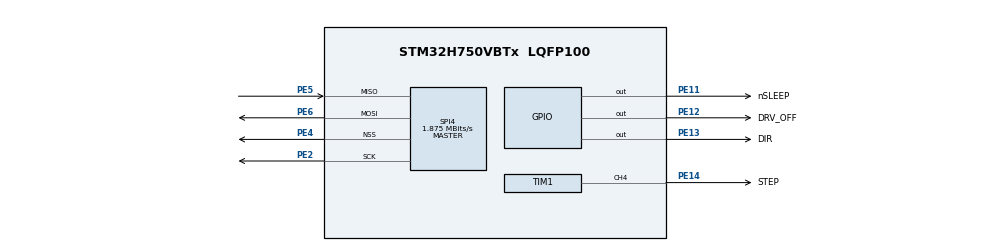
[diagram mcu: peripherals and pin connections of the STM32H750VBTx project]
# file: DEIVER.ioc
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CORTEX_M7.CPU_DCache=Enabled
CORTEX_M7.CPU_ICache=Enabled
Mcu.Family=STM32H7
Mcu.Name=STM32H750VBTx
Mcu.Package=LQFP100
NVIC.PriorityGroup=NVIC_PRIORITYGROUP_4
PE11.GPIO_Label=nSLEEP
PE11.GPIO_Speed=GPIO_SPEED_FREQ_MEDIUM
PE11.PinState=GPIO_PIN_SET
PE11.Signal=GPIO_Output
PE12.GPIO_Label=DRV_OFF
PE12.GPIO_Speed=GPIO_SPEED_FREQ_MEDIUM
PE12.Signal=GPIO_Output
PE13.GPIO_Label=DIR
PE13.GPIO_Speed=GPIO_SPEED_FREQ_MEDIUM
PE13.Signal=GPIO_Output
PE14.GPIO_Label=STEP
PE14.Signal=S_TIM1_CH4
PE2.Mode=Full_Duplex_Master
PE2.Signal=SPI4_SCK
PE4.Mode=NSS_Signal_Hard_Output
PE4.Signal=SPI4_NSS
PE5.Mode=Full_Duplex_Master
PE5.Signal=SPI4_MISO
PE6.Mode=Full_Duplex_Master
PE6.Signal=SPI4_MOSI
PH0-OSC_IN\ (PH0).Mode=HSE-External-Oscillator
PH0-OSC_IN\ (PH0).Signal=RCC_OSC_IN
PH1-OSC_OUT\ (PH1).Mode=HSE-External-Oscillator
PH1-OSC_OUT\ (PH1).Signal=RCC_OSC_OUT
ProjectManager.HeapSize=0x200
ProjectManager.StackSize=0x400
ProjectManager.TargetToolchain=MDK-ARM V5.27
RCC.ADCFreq_Value=50390625
RCC.APB1Freq_Value=120000000
RCC.APB2Freq_Value=120000000
RCC.APB3Freq_Value=120000000
RCC.APB4Freq_Value=120000000
RCC.CortexFreq_Value=480000000
RCC.D1PPRE=RCC_APB3_DIV2
RCC.D2PPRE1=RCC_APB1_DIV2
RCC.D2PPRE2=RCC_APB2_DIV2
RCC.D3PPRE=RCC_APB4_DIV2
RCC.DIVM1=5
RCC.DIVN1=192
RCC.HCLKFreq_Value=240000000
RCC.HPRE=RCC_HCLK_DIV2
RCC.PLLSourceVirtual=RCC_PLLSOURCE_HSE
RCC.SYSCLKFreq_VALUE=480000000
RCC.SYSCLKSource=RCC_SYSCLKSOURCE_PLLCLK
RCC.USBFreq_Value=480000000
SH.S_TIM1_CH4.0=TIM1_CH4,PWM Generation4 CH4
SPI4.BaudRatePrescaler=SPI_BAUDRATEPRESCALER_64
SPI4.CRCCalculation=SPI_CRCCALCULATION_DISABLE
SPI4.CalculateBaudRate=1.875 MBits/s
SPI4.DataSize=SPI_DATASIZE_16BIT
SPI4.Direction=SPI_DIRECTION_2LINES
SPI4.FifoThreshold=SPI_FIFO_THRESHOLD_08DATA
SPI4.Mode=SPI_MODE_MASTER
SPI4.NSSPolarity=SPI_NSS_POLARITY_LOW
SPI4.TIMode=SPI_TIMODE_ENABLE
SPI4.VirtualNSS=VM_NSSHARD
SPI4.VirtualType=VM_MASTER
TIM1.AutoReloadPreload=TIM_AUTORELOAD_PRELOAD_DISABLE
TIM1.Channel-PWM\ Generation4\ CH4=TIM_CHANNEL_4
TIM1.OCIdleState_4=TIM_OCIDLESTATE_SET
TIM1.Period=350
TIM1.Prescaler=239
TIM1.Pulse-PWM\ Generation4\ CH4=166
TIM1.RepetitionCounter=334
VP_TIM1_VS_ClockSourceINT.Mode=Internal
board=custom

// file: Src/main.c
/* USER CODE BEGIN Header */
/**
  ******************************************************************************
  * @file           : main.c
  * @brief          : Main program body
  ******************************************************************************
  * @attention
  *
  * <h2><center>&copy; Copyright (c) 2019 STMicroelectronics.
  * All rights reserved.</center></h2>
  *
  * This software component is licensed by ST under BSD 3-Clause license,
  * the "License"; You may not use this file except in compliance with the
  * License. You may obtain a copy of the License at:
  *                        opensource.org/licenses/BSD-3-Clause
  *
  ******************************************************************************
  */
/* USER CODE END Header */

#include "main.h"

/* USER CODE BEGIN Includes */
#include "drv8889.h"
/* USER CODE END Includes */

SPI_HandleTypeDef hspi4;

TIM_HandleTypeDef htim1;

void SystemClock_Config(void);
static void MX_GPIO_Init(void);
static void MX_SPI4_Init(void);
static void MX_TIM1_Init(void);

int main(void)
{

  /* Enable I-Cache---------------------------------------------------------*/
  SCB_EnableICache();

  /* Enable D-Cache---------------------------------------------------------*/
  SCB_EnableDCache();

  /* MCU Configuration--------------------------------------------------------*/

  /* Reset of all peripherals, Initializes the Flash interface and the Systick. */
  HAL_Init();

  /* Configure the system clock */
  SystemClock_Config();

  /* Initialize all configured peripherals */
  MX_GPIO_Init();
  MX_SPI4_Init();
  MX_TIM1_Init();
  /* USER CODE BEGIN 2 */
	HAL_TIM_PWM_Start(&htim1,TIM_CHANNEL_4);
	reset_Device8889();
  /* USER CODE END 2 */

  /* Infinite loop */
  while (1)
  {

  }
}

void SystemClock_Config(void)
{
  RCC_OscInitTypeDef RCC_OscInitStruct = {0};
  RCC_ClkInitTypeDef RCC_ClkInitStruct = {0};
  RCC_PeriphCLKInitTypeDef PeriphClkInitStruct = {0};

  /** Supply configuration update enable
  */
  HAL_PWREx_ConfigSupply(PWR_LDO_SUPPLY);
  /** Configure the main internal regulator output voltage
  */
  __HAL_PWR_VOLTAGESCALING_CONFIG(PWR_REGULATOR_VOLTAGE_SCALE0);

  while(!__HAL_PWR_GET_FLAG(PWR_FLAG_VOSRDY)) {}
  /** Initializes the CPU, AHB and APB busses clocks
  */
  RCC_OscInitStruct.OscillatorType = RCC_OSCILLATORTYPE_HSE;
  RCC_OscInitStruct.HSEState = RCC_HSE_ON;
  RCC_OscInitStruct.PLL.PLLState = RCC_PLL_ON;
  RCC_OscInitStruct.PLL.PLLSource = RCC_PLLSOURCE_HSE;
  RCC_OscInitStruct.PLL.PLLM = 5;
  RCC_OscInitStruct.PLL.PLLN = 192;
  RCC_OscInitStruct.PLL.PLLP = 2;
  RCC_OscInitStruct.PLL.PLLQ = 2;
  RCC_OscInitStruct.PLL.PLLR = 2;
  RCC_OscInitStruct.PLL.PLLRGE = RCC_PLL1VCIRANGE_2;
  RCC_OscInitStruct.PLL.PLLVCOSEL = RCC_PLL1VCOWIDE;
  RCC_OscInitStruct.PLL.PLLFRACN = 0;
  if (HAL_RCC_OscConfig(&RCC_OscInitStruct) != HAL_OK)
  {
    Error_Handler();
  }
  /** Initializes the CPU, AHB and APB busses clocks
  */
  RCC_ClkInitStruct.ClockType = RCC_CLOCKTYPE_HCLK|RCC_CLOCKTYPE_SYSCLK
                              |RCC_CLOCKTYPE_PCLK1|RCC_CLOCKTYPE_PCLK2
                              |RCC_CLOCKTYPE_D3PCLK1|RCC_CLOCKTYPE_D1PCLK1;
  RCC_ClkInitStruct.SYSCLKSource = RCC_SYSCLKSOURCE_PLLCLK;
  RCC_ClkInitStruct.SYSCLKDivider = RCC_SYSCLK_DIV1;
  RCC_ClkInitStruct.AHBCLKDivider = RCC_HCLK_DIV2;
  RCC_ClkInitStruct.APB3CLKDivider = RCC_APB3_DIV2;
  RCC_ClkInitStruct.APB1CLKDivider = RCC_APB1_DIV2;
  RCC_ClkInitStruct.APB2CLKDivider = RCC_APB2_DIV2;
  RCC_ClkInitStruct.APB4CLKDivider = RCC_APB4_DIV2;

  if (HAL_RCC_ClockConfig(&RCC_ClkInitStruct, FLASH_LATENCY_4) != HAL_OK)
  {
    Error_Handler();
  }
  PeriphClkInitStruct.PeriphClockSelection = RCC_PERIPHCLK_SPI4;
  PeriphClkInitStruct.Spi45ClockSelection = RCC_SPI45CLKSOURCE_D2PCLK1;
  if (HAL_RCCEx_PeriphCLKConfig(&PeriphClkInitStruct) != HAL_OK)
  {
    Error_Handler();
  }
}

static void MX_SPI4_Init(void)
{

  /* SPI4 parameter configuration*/
  hspi4.Instance = SPI4;
  hspi4.Init.Mode = SPI_MODE_MASTER;
  hspi4.Init.Direction = SPI_DIRECTION_2LINES;
  hspi4.Init.DataSize = SPI_DATASIZE_16BIT;
  hspi4.Init.NSS = SPI_NSS_HARD_OUTPUT;
  hspi4.Init.BaudRatePrescaler = SPI_BAUDRATEPRESCALER_64;
  hspi4.Init.TIMode = SPI_TIMODE_ENABLE;
  hspi4.Init.CRCCalculation = SPI_CRCCALCULATION_DISABLE;
  hspi4.Init.CRCPolynomial = 0x0;
  hspi4.Init.NSSPMode = SPI_NSS_PULSE_DISABLE;
  hspi4.Init.NSSPolarity = SPI_NSS_POLARITY_LOW;
  hspi4.Init.FifoThreshold = SPI_FIFO_THRESHOLD_08DATA;
  hspi4.Init.TxCRCInitializationPattern = SPI_CRC_INITIALIZATION_ALL_ZERO_PATTERN;
  hspi4.Init.RxCRCInitializationPattern = SPI_CRC_INITIALIZATION_ALL_ZERO_PATTERN;
  hspi4.Init.MasterReceiverAutoSusp = SPI_MASTER_RX_AUTOSUSP_DISABLE;
  hspi4.Init.MasterKeepIOState = SPI_MASTER_KEEP_IO_STATE_DISABLE;
  hspi4.Init.IOSwap = SPI_IO_SWAP_DISABLE;
  if (HAL_SPI_Init(&hspi4) != HAL_OK)
  {
    Error_Handler();
  }

}

static void MX_TIM1_Init(void)
{

  TIM_ClockConfigTypeDef sClockSourceConfig = {0};
  TIM_MasterConfigTypeDef sMasterConfig = {0};
  TIM_OC_InitTypeDef sConfigOC = {0};
  TIM_BreakDeadTimeConfigTypeDef sBreakDeadTimeConfig = {0};

  htim1.Instance = TIM1;
  htim1.Init.Prescaler = 239;
  htim1.Init.CounterMode = TIM_COUNTERMODE_UP;
  htim1.Init.Period = 350;
  htim1.Init.ClockDivision = TIM_CLOCKDIVISION_DIV1;
  htim1.Init.RepetitionCounter = 334;
  htim1.Init.AutoReloadPreload = TIM_AUTORELOAD_PRELOAD_DISABLE;
  if (HAL_TIM_Base_Init(&htim1) != HAL_OK)
  {
    Error_Handler();
  }
  sClockSourceConfig.ClockSource = TIM_CLOCKSOURCE_INTERNAL;
  if (HAL_TIM_ConfigClockSource(&htim1, &sClockSourceConfig) != HAL_OK)
  {
    Error_Handler();
  }
  if (HAL_TIM_PWM_Init(&htim1) != HAL_OK)
  {
    Error_Handler();
  }
  sMasterConfig.MasterOutputTrigger = TIM_TRGO_RESET;
  sMasterConfig.MasterOutputTrigger2 = TIM_TRGO2_RESET;
  sMasterConfig.MasterSlaveMode = TIM_MASTERSLAVEMODE_DISABLE;
  if (HAL_TIMEx_MasterConfigSynchronization(&htim1, &sMasterConfig) != HAL_OK)
  {
    Error_Handler();
  }
  sConfigOC.OCMode = TIM_OCMODE_PWM1;
  sConfigOC.Pulse = 166;
  sConfigOC.OCPolarity = TIM_OCPOLARITY_HIGH;
  sConfigOC.OCFastMode = TIM_OCFAST_DISABLE;
  sConfigOC.OCIdleState = TIM_OCIDLESTATE_SET;
  sConfigOC.OCNIdleState = TIM_OCNIDLESTATE_RESET;
  if (HAL_TIM_PWM_ConfigChannel(&htim1, &sConfigOC, TIM_CHANNEL_4) != HAL_OK)
  {
    Error_Handler();
  }
  sBreakDeadTimeConfig.OffStateRunMode = TIM_OSSR_DISABLE;
  sBreakDeadTimeConfig.OffStateIDLEMode = TIM_OSSI_DISABLE;
  sBreakDeadTimeConfig.LockLevel = TIM_LOCKLEVEL_OFF;
  sBreakDeadTimeConfig.DeadTime = 0;
  sBreakDeadTimeConfig.BreakState = TIM_BREAK_DISABLE;
  sBreakDeadTimeConfig.BreakPolarity = TIM_BREAKPOLARITY_HIGH;
  sBreakDeadTimeConfig.BreakFilter = 0;
  sBreakDeadTimeConfig.Break2State = TIM_BREAK2_DISABLE;
  sBreakDeadTimeConfig.Break2Polarity = TIM_BREAK2POLARITY_HIGH;
  sBreakDeadTimeConfig.Break2Filter = 0;
  sBreakDeadTimeConfig.AutomaticOutput = TIM_AUTOMATICOUTPUT_DISABLE;
  if (HAL_TIMEx_ConfigBreakDeadTime(&htim1, &sBreakDeadTimeConfig) != HAL_OK)
  {
    Error_Handler();
  }
  HAL_TIM_MspPostInit(&htim1);

}

static void MX_GPIO_Init(void)
{
  GPIO_InitTypeDef GPIO_InitStruct = {0};

  /* GPIO Ports Clock Enable */
  __HAL_RCC_GPIOE_CLK_ENABLE();
  __HAL_RCC_GPIOH_CLK_ENABLE();

  /*Configure GPIO pin Output Level */
  HAL_GPIO_WritePin(nSLEEP_GPIO_Port, nSLEEP_Pin, GPIO_PIN_SET);

  /*Configure GPIO pin Output Level */
  HAL_GPIO_WritePin(GPIOE, DRV_OFF_Pin|DIR_Pin, GPIO_PIN_RESET);

  /*Configure GPIO pins : nSLEEP_Pin DRV_OFF_Pin DIR_Pin */
  GPIO_InitStruct.Pin = nSLEEP_Pin|DRV_OFF_Pin|DIR_Pin;
  GPIO_InitStruct.Mode = GPIO_MODE_OUTPUT_PP;
  GPIO_InitStruct.Pull = GPIO_NOPULL;
  GPIO_InitStruct.Speed = GPIO_SPEED_FREQ_MEDIUM;
  HAL_GPIO_Init(GPIOE, &GPIO_InitStruct);

}

void Error_Handler(void)
{
}

/************************ (C) COPYRIGHT STMicroelectronics *****END OF FILE****/
